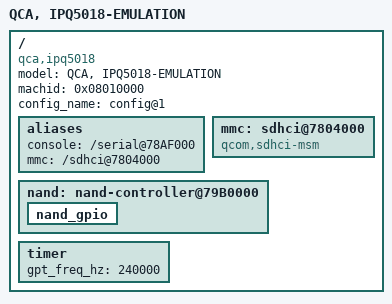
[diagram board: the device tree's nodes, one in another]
/*
 * Copyright (c) 2016-2019, The Linux Foundation. All rights reserved.
 *
 * This program is free software; you can redistribute it and/or modify
 * it under the terms of the GNU General Public License version 2 and
 * only version 2 as published by the Free Software Foundation.
 *
 * This program is distributed in the hope that it will be useful,
 * but WITHOUT ANY WARRANTY; without even the implied warranty of
 * MERCHANTABILITY or FITNESS FOR A PARTICULAR PURPOSE.  See the
 * GNU General Public License for more details.
 */

/dts-v1/;
#include "ipq5018-soc.dtsi"
/ {
	model ="QCA, IPQ5018-EMULATION";
	compatible = "qca,ipq5018", "qca,ipq5018-emulation";
	machid = <0x08010000>;
	config_name = "config@1";

	aliases {
		console = "/serial@78AF000";
		mmc = "/sdhci@7804000";
	};

	mmc: sdhci@7804000 {
		compatible = "qcom,sdhci-msm";
	};

	nand: nand-controller@79B0000 {
		status = "ok";
		nand_gpio {};
	};

	timer {
		gpt_freq_hz = <240000>;
	};

};
